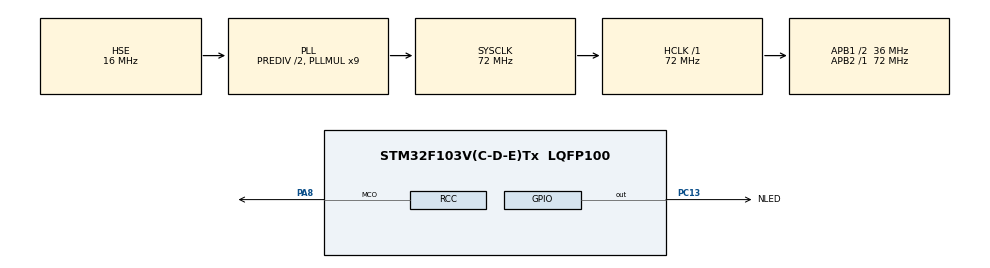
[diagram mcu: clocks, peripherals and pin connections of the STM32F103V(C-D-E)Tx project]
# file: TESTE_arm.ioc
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Mcu.Family=STM32F1
Mcu.Name=STM32F103V(C-D-E)Tx
Mcu.Package=LQFP100
NVIC.PriorityGroup=NVIC_PRIORITYGROUP_4
OSC_IN.Mode=HSE-External-Oscillator
OSC_IN.Signal=RCC_OSC_IN
OSC_OUT.Mode=HSE-External-Oscillator
OSC_OUT.Signal=RCC_OSC_OUT
PA13.Mode=JTAG_5_pins
PA13.Signal=SYS_JTMS-SWDIO
PA14.Mode=JTAG_5_pins
PA14.Signal=SYS_JTCK-SWCLK
PA15.Mode=JTAG_5_pins
PA15.Signal=SYS_JTDI
PA8.Mode=Clock-out
PA8.Signal=RCC_MCO
PB3.Mode=JTAG_5_pins
PB3.Signal=SYS_JTDO-TRACESWO
PB4.Mode=JTAG_5_pins
PB4.Signal=SYS_NJTRST
PC13-TAMPER-RTC.GPIO_Label=NLED
PC13-TAMPER-RTC.GPIO_Speed=GPIO_SPEED_FREQ_HIGH
PC13-TAMPER-RTC.PinState=GPIO_PIN_RESET
PC13-TAMPER-RTC.Signal=GPIO_Output
PC14-OSC32_IN.Mode=LSE-External-Oscillator
PC14-OSC32_IN.Signal=RCC_OSC32_IN
PC15-OSC32_OUT.Mode=LSE-External-Oscillator
PC15-OSC32_OUT.Signal=RCC_OSC32_OUT
ProjectManager.HeapSize=0x200
ProjectManager.StackSize=0x400
ProjectManager.TargetToolchain=Makefile
RCC.AHBFreq_Value=72000000
RCC.APB1CLKDivider=RCC_HCLK_DIV2
RCC.APB1Freq_Value=36000000
RCC.APB1TimFreq_Value=72000000
RCC.APB2Freq_Value=72000000
RCC.APB2TimFreq_Value=72000000
RCC.HCLKFreq_Value=72000000
RCC.HSEDivPLL=RCC_HSE_PREDIV_DIV2
RCC.HSE_VALUE=16000000
RCC.PLLMUL=RCC_PLL_MUL9
RCC.PLLSourceVirtual=RCC_PLLSOURCE_HSE
RCC.RCC_MCOSource=RCC_MCO1SOURCE_HSE
RCC.SYSCLKFreq_VALUE=72000000
RCC.SYSCLKSource=RCC_SYSCLKSOURCE_PLLCLK
RCC.USBFreq_Value=72000000
board=custom

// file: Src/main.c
/* USER CODE BEGIN Header */
/**
  ******************************************************************************
  * @file           : main.c
  * @brief          : Main program body
  ******************************************************************************
  * @attention
  *
  * <h2><center>&copy; Copyright (c) 2020 STMicroelectronics.
  * All rights reserved.</center></h2>
  *
  * This software component is licensed by ST under BSD 3-Clause license,
  * the "License"; You may not use this file except in compliance with the
  * License. You may obtain a copy of the License at:
  *                        opensource.org/licenses/BSD-3-Clause
  *
  ******************************************************************************
  */
/* USER CODE END Header */

#include "main.h"
#include "gpio.h"

void SystemClock_Config(void);

int main(void)
{

  /* MCU Configuration--------------------------------------------------------*/

  /* Reset of all peripherals, Initializes the Flash interface and the Systick. */
  HAL_Init();

  /* Configure the system clock */
  SystemClock_Config();

  /* Initialize all configured peripherals */
  MX_GPIO_Init();

  /* Infinite loop */
  /* USER CODE BEGIN WHILE */
	HAL_GPIO_WritePin(NLED_GPIO_Port, NLED_Pin, GPIO_PIN_SET);
	while(1) {
		HAL_GPIO_TogglePin(NLED_GPIO_Port, NLED_Pin);
		HAL_Delay(100);
		HAL_GPIO_TogglePin(NLED_GPIO_Port, NLED_Pin);
		HAL_Delay(100);
		HAL_GPIO_TogglePin(NLED_GPIO_Port, NLED_Pin);
		HAL_Delay(100);
		HAL_GPIO_TogglePin(NLED_GPIO_Port, NLED_Pin);
		HAL_Delay(100);

		HAL_Delay(400);
    /* USER CODE END WHILE */

	}
}

void SystemClock_Config(void)
{
  RCC_OscInitTypeDef RCC_OscInitStruct = {0};
  RCC_ClkInitTypeDef RCC_ClkInitStruct = {0};

  /** Initializes the CPU, AHB and APB busses clocks
  */
  RCC_OscInitStruct.OscillatorType = RCC_OSCILLATORTYPE_HSE;
  RCC_OscInitStruct.HSEState = RCC_HSE_ON;
  RCC_OscInitStruct.HSEPredivValue = RCC_HSE_PREDIV_DIV2;
  RCC_OscInitStruct.HSIState = RCC_HSI_ON;
  RCC_OscInitStruct.PLL.PLLState = RCC_PLL_ON;
  RCC_OscInitStruct.PLL.PLLSource = RCC_PLLSOURCE_HSE;
  RCC_OscInitStruct.PLL.PLLMUL = RCC_PLL_MUL9;
  if (HAL_RCC_OscConfig(&RCC_OscInitStruct) != HAL_OK)
  {
    Error_Handler();
  }
  /** Initializes the CPU, AHB and APB busses clocks
  */
  RCC_ClkInitStruct.ClockType = RCC_CLOCKTYPE_HCLK|RCC_CLOCKTYPE_SYSCLK
                              |RCC_CLOCKTYPE_PCLK1|RCC_CLOCKTYPE_PCLK2;
  RCC_ClkInitStruct.SYSCLKSource = RCC_SYSCLKSOURCE_PLLCLK;
  RCC_ClkInitStruct.AHBCLKDivider = RCC_SYSCLK_DIV1;
  RCC_ClkInitStruct.APB1CLKDivider = RCC_HCLK_DIV2;
  RCC_ClkInitStruct.APB2CLKDivider = RCC_HCLK_DIV1;

  if (HAL_RCC_ClockConfig(&RCC_ClkInitStruct, FLASH_LATENCY_2) != HAL_OK)
  {
    Error_Handler();
  }
  HAL_RCC_MCOConfig(RCC_MCO, RCC_MCO1SOURCE_HSE, RCC_MCODIV_1);
}

void Error_Handler(void)
{
}

/************************ (C) COPYRIGHT STMicroelectronics *****END OF FILE****/
